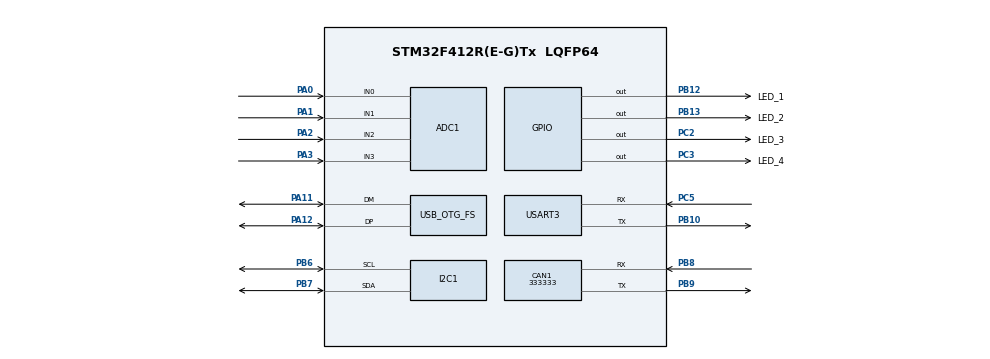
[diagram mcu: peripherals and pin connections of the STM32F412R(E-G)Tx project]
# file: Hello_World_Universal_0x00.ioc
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ADC1.Channel-0\#ChannelRegularConversion=ADC_CHANNEL_0
ADC1.NbrOfConversionFlag=1
ADC1.Rank-0\#ChannelRegularConversion=1
ADC1.SamplingTime-0\#ChannelRegularConversion=ADC_SAMPLETIME_3CYCLES
ADC1.master=1
CAN1.CalculateBaudRate=333333
CAN1.CalculateTimeBit=3000
CAN1.CalculateTimeQuantum=1000.0
Mcu.Family=STM32F4
Mcu.Name=STM32F412R(E-G)Tx
Mcu.Package=LQFP64
NVIC.PriorityGroup=NVIC_PRIORITYGROUP_4
PA0.Signal=ADCx_IN0
PA1.Signal=ADCx_IN1
PA11.Mode=Device_Only
PA11.Signal=USB_OTG_FS_DM
PA12.Mode=Device_Only
PA12.Signal=USB_OTG_FS_DP
PA13.Mode=Serial_Wire
PA13.Signal=SYS_JTMS-SWDIO
PA14.Mode=Serial_Wire
PA14.Signal=SYS_JTCK-SWCLK
PA2.Signal=ADCx_IN2
PA3.Signal=ADCx_IN3
PB10.Mode=Asynchronous
PB10.Signal=USART3_TX
PB12.GPIO_Label=LED_1
PB12.Signal=GPIO_Output
PB13.GPIO_Label=LED_2
PB13.Signal=GPIO_Output
PB6.Mode=I2C
PB6.Signal=I2C1_SCL
PB7.Mode=I2C
PB7.Signal=I2C1_SDA
PB8.Mode=CAN_Activate
PB8.Signal=CAN1_RX
PB9.Mode=CAN_Activate
PB9.Signal=CAN1_TX
PC2.GPIO_Label=LED_3
PC2.Signal=GPIO_Output
PC3.GPIO_Label=LED_4
PC3.Signal=GPIO_Output
PC5.Mode=Asynchronous
PC5.Signal=USART3_RX
PH0\ -\ OSC_IN.Mode=HSE-External-Oscillator
PH0\ -\ OSC_IN.Signal=RCC_OSC_IN
PH1\ -\ OSC_OUT.Mode=HSE-External-Oscillator
PH1\ -\ OSC_OUT.Signal=RCC_OSC_OUT
ProjectManager.HeapSize=0x200
ProjectManager.StackSize=0x400
ProjectManager.TargetToolchain=STM32CubeIDE
RCC.CortexFreq_Value=16000000
RCC.HSE_VALUE=16000000
RCC.PLLM=8
RCC.PLLN=72
RCC.PLLQ=3
RCC.USBFreq_Value=48000000
RCC.VCOOutputFreq_Value=144000000
SH.ADCx_IN0.0=ADC1_IN0,IN0
SH.ADCx_IN1.0=ADC1_IN1,IN1
SH.ADCx_IN2.0=ADC1_IN2,IN2
SH.ADCx_IN3.0=ADC1_IN3,IN3
USART3.VirtualMode=VM_ASYNC
USB_OTG_FS.VirtualMode=Device_Only
board=custom

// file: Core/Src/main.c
/* USER CODE BEGIN Header */
/**
  ******************************************************************************
  * @file           : main.c
  * @brief          : Main program body
  ******************************************************************************
  * @attention
  *
  * Copyright (c) 2023 STMicroelectronics.
  * All rights reserved.
  *
  * This software is licensed under terms that can be found in the LICENSE file
  * in the root directory of this software component.
  * If no LICENSE file comes with this software, it is provided AS-IS.
  *
  ******************************************************************************
  */
/* USER CODE END Header */
#include "main.h"

ADC_HandleTypeDef hadc1;

CAN_HandleTypeDef hcan1;

I2C_HandleTypeDef hi2c1;

UART_HandleTypeDef huart3;

PCD_HandleTypeDef hpcd_USB_OTG_FS;

void SystemClock_Config(void);
static void MX_GPIO_Init(void);
static void MX_ADC1_Init(void);
static void MX_CAN1_Init(void);
static void MX_I2C1_Init(void);
static void MX_USART3_UART_Init(void);
static void MX_USB_OTG_FS_PCD_Init(void);

int main(void)
{

  /* MCU Configuration--------------------------------------------------------*/

  /* Reset of all peripherals, Initializes the Flash interface and the Systick. */
  HAL_Init();

  /* Configure the system clock */
  SystemClock_Config();

  /* Initialize all configured peripherals */
  MX_GPIO_Init();
  MX_ADC1_Init();
  MX_CAN1_Init();
  MX_I2C1_Init();
  MX_USART3_UART_Init();
  MX_USB_OTG_FS_PCD_Init();

  /* Infinite loop */
  while (1)
  {

    /* USER CODE BEGIN 3 */

	  HAL_GPIO_TogglePin (GPIOC, LED_3_Pin);
	  HAL_Delay (100);
  }
  /* USER CODE END 3 */
}

void SystemClock_Config(void)
{
  RCC_OscInitTypeDef RCC_OscInitStruct = {0};
  RCC_ClkInitTypeDef RCC_ClkInitStruct = {0};

  /** Configure the main internal regulator output voltage
  */
  __HAL_RCC_PWR_CLK_ENABLE();
  __HAL_PWR_VOLTAGESCALING_CONFIG(PWR_REGULATOR_VOLTAGE_SCALE1);

  /** Initializes the RCC Oscillators according to the specified parameters
  * in the RCC_OscInitTypeDef structure.
  */
  RCC_OscInitStruct.OscillatorType = RCC_OSCILLATORTYPE_HSI|RCC_OSCILLATORTYPE_HSE;
  RCC_OscInitStruct.HSEState = RCC_HSE_ON;
  RCC_OscInitStruct.HSIState = RCC_HSI_ON;
  RCC_OscInitStruct.HSICalibrationValue = RCC_HSICALIBRATION_DEFAULT;
  RCC_OscInitStruct.PLL.PLLState = RCC_PLL_ON;
  RCC_OscInitStruct.PLL.PLLSource = RCC_PLLSOURCE_HSE;
  RCC_OscInitStruct.PLL.PLLM = 8;
  RCC_OscInitStruct.PLL.PLLN = 72;
  RCC_OscInitStruct.PLL.PLLP = RCC_PLLP_DIV2;
  RCC_OscInitStruct.PLL.PLLQ = 3;
  RCC_OscInitStruct.PLL.PLLR = 2;
  if (HAL_RCC_OscConfig(&RCC_OscInitStruct) != HAL_OK)
  {
    Error_Handler();
  }

  /** Initializes the CPU, AHB and APB buses clocks
  */
  RCC_ClkInitStruct.ClockType = RCC_CLOCKTYPE_HCLK|RCC_CLOCKTYPE_SYSCLK
                              |RCC_CLOCKTYPE_PCLK1|RCC_CLOCKTYPE_PCLK2;
  RCC_ClkInitStruct.SYSCLKSource = RCC_SYSCLKSOURCE_HSI;
  RCC_ClkInitStruct.AHBCLKDivider = RCC_SYSCLK_DIV1;
  RCC_ClkInitStruct.APB1CLKDivider = RCC_HCLK_DIV1;
  RCC_ClkInitStruct.APB2CLKDivider = RCC_HCLK_DIV1;

  if (HAL_RCC_ClockConfig(&RCC_ClkInitStruct, FLASH_LATENCY_0) != HAL_OK)
  {
    Error_Handler();
  }
}

static void MX_ADC1_Init(void)
{

  ADC_ChannelConfTypeDef sConfig = {0};

  /** Configure the global features of the ADC (Clock, Resolution, Data Alignment and number of conversion)
  */
  hadc1.Instance = ADC1;
  hadc1.Init.ClockPrescaler = ADC_CLOCK_SYNC_PCLK_DIV2;
  hadc1.Init.Resolution = ADC_RESOLUTION_12B;
  hadc1.Init.ScanConvMode = DISABLE;
  hadc1.Init.ContinuousConvMode = DISABLE;
  hadc1.Init.DiscontinuousConvMode = DISABLE;
  hadc1.Init.ExternalTrigConvEdge = ADC_EXTERNALTRIGCONVEDGE_NONE;
  hadc1.Init.ExternalTrigConv = ADC_SOFTWARE_START;
  hadc1.Init.DataAlign = ADC_DATAALIGN_RIGHT;
  hadc1.Init.NbrOfConversion = 1;
  hadc1.Init.DMAContinuousRequests = DISABLE;
  hadc1.Init.EOCSelection = ADC_EOC_SINGLE_CONV;
  if (HAL_ADC_Init(&hadc1) != HAL_OK)
  {
    Error_Handler();
  }

  /** Configure for the selected ADC regular channel its corresponding rank in the sequencer and its sample time.
  */
  sConfig.Channel = ADC_CHANNEL_0;
  sConfig.Rank = 1;
  sConfig.SamplingTime = ADC_SAMPLETIME_3CYCLES;
  if (HAL_ADC_ConfigChannel(&hadc1, &sConfig) != HAL_OK)
  {
    Error_Handler();
  }

}

static void MX_CAN1_Init(void)
{

  hcan1.Instance = CAN1;
  hcan1.Init.Prescaler = 16;
  hcan1.Init.Mode = CAN_MODE_NORMAL;
  hcan1.Init.SyncJumpWidth = CAN_SJW_1TQ;
  hcan1.Init.TimeSeg1 = CAN_BS1_1TQ;
  hcan1.Init.TimeSeg2 = CAN_BS2_1TQ;
  hcan1.Init.TimeTriggeredMode = DISABLE;
  hcan1.Init.AutoBusOff = DISABLE;
  hcan1.Init.AutoWakeUp = DISABLE;
  hcan1.Init.AutoRetransmission = DISABLE;
  hcan1.Init.ReceiveFifoLocked = DISABLE;
  hcan1.Init.TransmitFifoPriority = DISABLE;
  if (HAL_CAN_Init(&hcan1) != HAL_OK)
  {
    Error_Handler();
  }

}

static void MX_I2C1_Init(void)
{

  hi2c1.Instance = I2C1;
  hi2c1.Init.ClockSpeed = 100000;
  hi2c1.Init.DutyCycle = I2C_DUTYCYCLE_2;
  hi2c1.Init.OwnAddress1 = 0;
  hi2c1.Init.AddressingMode = I2C_ADDRESSINGMODE_7BIT;
  hi2c1.Init.DualAddressMode = I2C_DUALADDRESS_DISABLE;
  hi2c1.Init.OwnAddress2 = 0;
  hi2c1.Init.GeneralCallMode = I2C_GENERALCALL_DISABLE;
  hi2c1.Init.NoStretchMode = I2C_NOSTRETCH_DISABLE;
  if (HAL_I2C_Init(&hi2c1) != HAL_OK)
  {
    Error_Handler();
  }

}

static void MX_USART3_UART_Init(void)
{

  huart3.Instance = USART3;
  huart3.Init.BaudRate = 115200;
  huart3.Init.WordLength = UART_WORDLENGTH_8B;
  huart3.Init.StopBits = UART_STOPBITS_1;
  huart3.Init.Parity = UART_PARITY_NONE;
  huart3.Init.Mode = UART_MODE_TX_RX;
  huart3.Init.HwFlowCtl = UART_HWCONTROL_NONE;
  huart3.Init.OverSampling = UART_OVERSAMPLING_16;
  if (HAL_UART_Init(&huart3) != HAL_OK)
  {
    Error_Handler();
  }

}

static void MX_USB_OTG_FS_PCD_Init(void)
{

  hpcd_USB_OTG_FS.Instance = USB_OTG_FS;
  hpcd_USB_OTG_FS.Init.dev_endpoints = 6;
  hpcd_USB_OTG_FS.Init.speed = PCD_SPEED_FULL;
  hpcd_USB_OTG_FS.Init.dma_enable = DISABLE;
  hpcd_USB_OTG_FS.Init.phy_itface = PCD_PHY_EMBEDDED;
  hpcd_USB_OTG_FS.Init.Sof_enable = DISABLE;
  hpcd_USB_OTG_FS.Init.low_power_enable = DISABLE;
  hpcd_USB_OTG_FS.Init.lpm_enable = DISABLE;
  hpcd_USB_OTG_FS.Init.battery_charging_enable = DISABLE;
  hpcd_USB_OTG_FS.Init.vbus_sensing_enable = DISABLE;
  hpcd_USB_OTG_FS.Init.use_dedicated_ep1 = DISABLE;
  if (HAL_PCD_Init(&hpcd_USB_OTG_FS) != HAL_OK)
  {
    Error_Handler();
  }

}

static void MX_GPIO_Init(void)
{
  GPIO_InitTypeDef GPIO_InitStruct = {0};

  /* GPIO Ports Clock Enable */
  __HAL_RCC_GPIOH_CLK_ENABLE();
  __HAL_RCC_GPIOC_CLK_ENABLE();
  __HAL_RCC_GPIOA_CLK_ENABLE();
  __HAL_RCC_GPIOB_CLK_ENABLE();

  /*Configure GPIO pin Output Level */
  HAL_GPIO_WritePin(GPIOC, LED_3_Pin|LED_4_Pin, GPIO_PIN_RESET);

  /*Configure GPIO pin Output Level */
  HAL_GPIO_WritePin(GPIOB, LED_1_Pin|LED_2_Pin, GPIO_PIN_RESET);

  /*Configure GPIO pins : LED_3_Pin LED_4_Pin */
  GPIO_InitStruct.Pin = LED_3_Pin|LED_4_Pin;
  GPIO_InitStruct.Mode = GPIO_MODE_OUTPUT_PP;
  GPIO_InitStruct.Pull = GPIO_NOPULL;
  GPIO_InitStruct.Speed = GPIO_SPEED_FREQ_LOW;
  HAL_GPIO_Init(GPIOC, &GPIO_InitStruct);

  /*Configure GPIO pins : LED_1_Pin LED_2_Pin */
  GPIO_InitStruct.Pin = LED_1_Pin|LED_2_Pin;
  GPIO_InitStruct.Mode = GPIO_MODE_OUTPUT_PP;
  GPIO_InitStruct.Pull = GPIO_NOPULL;
  GPIO_InitStruct.Speed = GPIO_SPEED_FREQ_LOW;
  HAL_GPIO_Init(GPIOB, &GPIO_InitStruct);

}

void Error_Handler(void)
{
  __disable_irq();
  while (1)
  {
  }
}
